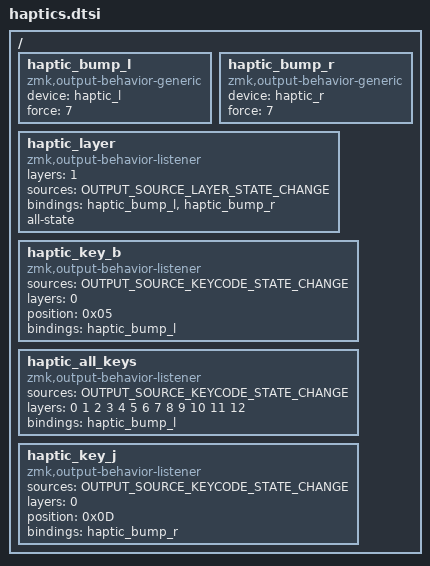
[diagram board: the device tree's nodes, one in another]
/* enums to set in sources to filter events in zmk,output-behavior-listener */
#define OUTPUT_SOURCE_LAYER_STATE_CHANGE        1
#define OUTPUT_SOURCE_POSITION_STATE_CHANGE     2
#define OUTPUT_SOURCE_KEYCODE_STATE_CHANGE      3
#define OUTPUT_SOURCE_MOUSE_BUTTON_STATE_CHANGE 4
#define OUTPUT_SOURCE_MOUSE_WHEEL_STATE_CHANGE  5
#define OUTPUT_SOURCE_TRANSPORT                 6

/ {
   haptic_bump_l: haptic_bump_l {
        compatible = "zmk,output-behavior-generic";
        #binding-cells = <0>;
        device = <&haptic_l>;
        force = <7>;
    };

    haptic_bump_r: haptic_bump_r {
        compatible = "zmk,output-behavior-generic";
        #binding-cells = <0>;
        device = <&haptic_r>;
        force = <7>;
    };

    haptic_layer {
        compatible = "zmk,output-behavior-listener";
        layers = <1>;
        sources = <OUTPUT_SOURCE_LAYER_STATE_CHANGE>;
        bindings = <&haptic_bump_l &haptic_bump_r>;
        all-state;
    };

    haptic_key_b {
        compatible = "zmk,output-behavior-listener";
        sources = <OUTPUT_SOURCE_KEYCODE_STATE_CHANGE>;
        layers = <0>;
        position = <0x05>;
        bindings = <&haptic_bump_l>;
    };

    haptic_all_keys {
        compatible = "zmk,output-behavior-listener";
        sources = <OUTPUT_SOURCE_KEYCODE_STATE_CHANGE>;
        layers = <0 1 2 3 4 5 6 7 8 9 10 11 12>;
        bindings = <&haptic_bump_l>;
    };


    haptic_key_j {
        compatible = "zmk,output-behavior-listener";
        sources = <OUTPUT_SOURCE_KEYCODE_STATE_CHANGE>;
        layers = <0>;
        position = <0x0D>;
        bindings = <&haptic_bump_r>;
    };	
};
